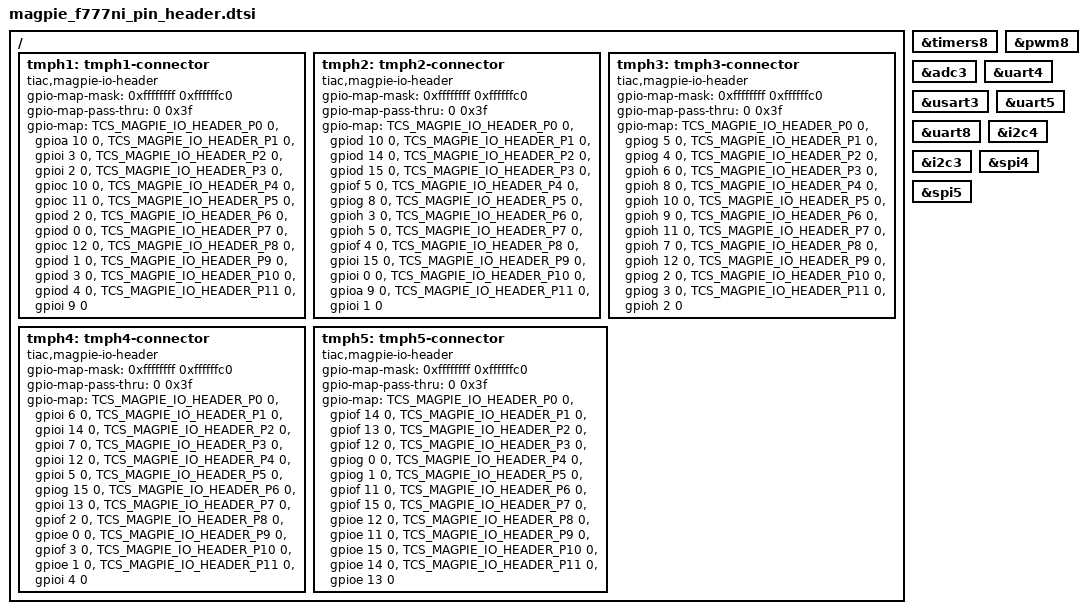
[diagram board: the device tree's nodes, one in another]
/*
 * SPDX-FileCopyrightText: Copyright (c) 2021-2026 TiaC Systems
 * SPDX-FileCopyrightText: Copyright (c) 2021 Li-Pro.Net
 * SPDX-License-Identifier: Apache-2.0
 */

#include <zephyr/dt-bindings/gpio/tiac-magpie-io-header.h>

/ {
	tmph1: tmph1-connector {
		compatible = "tiac,magpie-io-header";
		#gpio-cells = <2>;
		gpio-map-mask = <0xffffffff 0xffffffc0>;
		gpio-map-pass-thru = <0 0x3f>;
		gpio-map = <TCS_MAGPIE_IO_HEADER_P0 0 &gpioa 10 0>,	/* TMPH1_PA10 */
			   <TCS_MAGPIE_IO_HEADER_P1 0 &gpioi 3 0>,	/* TMPH1_PI3 */
			   <TCS_MAGPIE_IO_HEADER_P2 0 &gpioi 2 0>,	/* TMPH1_PI2_PWM84 */
			   <TCS_MAGPIE_IO_HEADER_P3 0 &gpioc 10 0>,	/* TMPH1_PC10_TXD3 */
			   <TCS_MAGPIE_IO_HEADER_P4 0 &gpioc 11 0>,	/* TMPH1_PC11_RXD3 */
			   <TCS_MAGPIE_IO_HEADER_P5 0 &gpiod 2 0>,	/* TMPH1_PD2_RXD5 */
			   <TCS_MAGPIE_IO_HEADER_P6 0 &gpiod 0 0>,	/* TMPH1_PD0_RXD4 */
			   <TCS_MAGPIE_IO_HEADER_P7 0 &gpioc 12 0>,	/* TMPH1_PC12_TXD5 */
			   <TCS_MAGPIE_IO_HEADER_P8 0 &gpiod 1 0>,	/* TMPH1_PD1_TXD4 */
			   <TCS_MAGPIE_IO_HEADER_P9 0 &gpiod 3 0>,	/* TMPH1_PD3 */
			   <TCS_MAGPIE_IO_HEADER_P10 0 &gpiod 4 0>,	/* TMPH1_PD4 */
			   <TCS_MAGPIE_IO_HEADER_P11 0 &gpioi 9 0>;	/* TMPH1_PI9 */
	}; // tmph1

	tmph2: tmph2-connector {
		compatible = "tiac,magpie-io-header";
		#gpio-cells = <2>;
		gpio-map-mask = <0xffffffff 0xffffffc0>;
		gpio-map-pass-thru = <0 0x3f>;
		gpio-map = <TCS_MAGPIE_IO_HEADER_P0 0 &gpiod 10 0>,	/* TMPH2_PD10 */
			   <TCS_MAGPIE_IO_HEADER_P1 0 &gpiod 14 0>,	/* TMPH2_PD14_CTS8 */
			   <TCS_MAGPIE_IO_HEADER_P2 0 &gpiod 15 0>,	/* TMPH2_PD15_RTS8 */
			   <TCS_MAGPIE_IO_HEADER_P3 0 &gpiof 5 0>,	/* TMPH2_PF5_ADC315 */
			   <TCS_MAGPIE_IO_HEADER_P4 0 &gpiog 8 0>,	/* TMPH2_PG8 */
			   <TCS_MAGPIE_IO_HEADER_P5 0 &gpioh 3 0>,	/* TMPH2_PH3 */
			   <TCS_MAGPIE_IO_HEADER_P6 0 &gpioh 5 0>,	/* TMPH2_PH5_NSS5 */
			   <TCS_MAGPIE_IO_HEADER_P7 0 &gpiof 4 0>,	/* TMPH2_PF4_ADC314 */
			   <TCS_MAGPIE_IO_HEADER_P8 0 &gpioi 15 0>,	/* TMPH2_PI15 */
			   <TCS_MAGPIE_IO_HEADER_P9 0 &gpioi 0 0>,	/* TMPH2_PI0 */
			   <TCS_MAGPIE_IO_HEADER_P10 0 &gpioa 9 0>,	/* TMPH2_PA9 */
			   <TCS_MAGPIE_IO_HEADER_P11 0 &gpioi 1 0>;	/* TMPH2_PI1 */
	}; // tmph2

	tmph3: tmph3-connector {
		compatible = "tiac,magpie-io-header";
		#gpio-cells = <2>;
		gpio-map-mask = <0xffffffff 0xffffffc0>;
		gpio-map-pass-thru = <0 0x3f>;
		gpio-map = <TCS_MAGPIE_IO_HEADER_P0 0 &gpiog 5 0>,	/* TMPH3_PG5 */
			   <TCS_MAGPIE_IO_HEADER_P1 0 &gpiog 4 0>,	/* TMPH3_PG4 */
			   <TCS_MAGPIE_IO_HEADER_P2 0 &gpioh 6 0>,	/* TMPH3_PH6_SCK5 */
			   <TCS_MAGPIE_IO_HEADER_P3 0 &gpioh 8 0>,	/* TMPH3_PH8_SDA3 */
			   <TCS_MAGPIE_IO_HEADER_P4 0 &gpioh 10 0>,	/* TMPH3_PH10 */
			   <TCS_MAGPIE_IO_HEADER_P5 0 &gpioh 9 0>,	/* TMPH3_PH9 */
			   <TCS_MAGPIE_IO_HEADER_P6 0 &gpioh 11 0>,	/* TMPH3_PH11 */
			   <TCS_MAGPIE_IO_HEADER_P7 0 &gpioh 7 0>,	/* TMPH3_PH7_SCL3_MISO5 */
			   <TCS_MAGPIE_IO_HEADER_P8 0 &gpioh 12 0>,	/* TMPH3_PH12 */
			   <TCS_MAGPIE_IO_HEADER_P9 0 &gpiog 2 0>,	/* TMPH3_PG2 */
			   <TCS_MAGPIE_IO_HEADER_P10 0 &gpiog 3 0>,	/* TMPH3_PG3 */
			   <TCS_MAGPIE_IO_HEADER_P11 0 &gpioh 2 0>;	/* TMPH3_PH2 */
	}; // tmph3

	tmph4: tmph4-connector {
		compatible = "tiac,magpie-io-header";
		#gpio-cells = <2>;
		gpio-map-mask = <0xffffffff 0xffffffc0>;
		gpio-map-pass-thru = <0 0x3f>;
		gpio-map = <TCS_MAGPIE_IO_HEADER_P0 0 &gpioi 6 0>,	/* TMPH4_PI6_PWM82 */
			   <TCS_MAGPIE_IO_HEADER_P1 0 &gpioi 14 0>,	/* TMPH4_PI14 */
			   <TCS_MAGPIE_IO_HEADER_P2 0 &gpioi 7 0>,	/* TMPH4_PI7_PWM83 */
			   <TCS_MAGPIE_IO_HEADER_P3 0 &gpioi 12 0>,	/* TMPH4_PI12 */
			   <TCS_MAGPIE_IO_HEADER_P4 0 &gpioi 5 0>,	/* TMPH4_PI5_PWM81 */
			   <TCS_MAGPIE_IO_HEADER_P5 0 &gpiog 15 0>,	/* TMPH4_PG15 */
			   <TCS_MAGPIE_IO_HEADER_P6 0 &gpioi 13 0>,	/* TMPH4_PI13 */
			   <TCS_MAGPIE_IO_HEADER_P7 0 &gpiof 2 0>,	/* TMPH4_PF2 */
			   <TCS_MAGPIE_IO_HEADER_P8 0 &gpioe 0 0>,	/* TMPH4_PE0_RXD8 */
			   <TCS_MAGPIE_IO_HEADER_P9 0 &gpiof 3 0>,	/* TMPH4_PF3_ADC39 */
			   <TCS_MAGPIE_IO_HEADER_P10 0 &gpioe 1 0>,	/* TMPH4_PE1_TXD8 */
			   <TCS_MAGPIE_IO_HEADER_P11 0 &gpioi 4 0>;	/* TMPH4_PI4 */
	}; // tmph4

	tmph5: tmph5-connector {
		compatible = "tiac,magpie-io-header";
		#gpio-cells = <2>;
		gpio-map-mask = <0xffffffff 0xffffffc0>;
		gpio-map-pass-thru = <0 0x3f>;
		gpio-map = <TCS_MAGPIE_IO_HEADER_P0 0 &gpiof 14 0>,	/* TMPH5_PF14_SCL4 */
			   <TCS_MAGPIE_IO_HEADER_P1 0 &gpiof 13 0>,	/* TMPH5_PF13 */
			   <TCS_MAGPIE_IO_HEADER_P2 0 &gpiof 12 0>,	/* TMPH5_PF12 */
			   <TCS_MAGPIE_IO_HEADER_P3 0 &gpiog 0 0>,	/* TMPH5_PG0 */
			   <TCS_MAGPIE_IO_HEADER_P4 0 &gpiog 1 0>,	/* TMPH5_PG1 */
			   <TCS_MAGPIE_IO_HEADER_P5 0 &gpiof 11 0>,	/* TMPH5_PF11_MOSI5 */
			   <TCS_MAGPIE_IO_HEADER_P6 0 &gpiof 15 0>,	/* TMPH5_PF15_SDA4 */
			   <TCS_MAGPIE_IO_HEADER_P7 0 &gpioe 12 0>,	/* TMPH5_PE12_SCK4 */
			   <TCS_MAGPIE_IO_HEADER_P8 0 &gpioe 11 0>,	/* TMPH5_PE11_NSS4 */
			   <TCS_MAGPIE_IO_HEADER_P9 0 &gpioe 15 0>,	/* TMPH5_PE15 */
			   <TCS_MAGPIE_IO_HEADER_P10 0 &gpioe 14 0>,	/* TMPH5_PE14_MOSI4 */
			   <TCS_MAGPIE_IO_HEADER_P11 0 &gpioe 13 0>;	/* TMPH5_PE13_MISO4 */
	}; // tmph5
};

tmph_timers: &timers8 {};
tmph_pwms: &pwm8 {};
tmph_adc: &adc3 {};

tmph_serial1: &uart4 {};
tmph_serial2: &usart3 {};
tmph_serial3: &uart5 {};
tmph_serial4: &uart8 {};
tmph_serial: &tmph_serial1 {};

tmph_i2c1: &i2c4 {};
tmph_i2c2: &i2c3 {};
tmph_i2c: &tmph_i2c1 {};

tmph_spi1: &spi4 {};
tmph_spi2: &spi5 {};
tmph_spi: &tmph_spi1 {};
